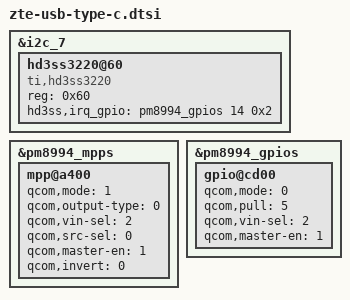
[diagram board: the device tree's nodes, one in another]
/*
 * Copyright (c) 2015 The Linux Foundation. All rights reserved.
 *
 * This program is free software; you can redistribute it and/or modify
 * it under the terms of the GNU General Public License version 2 and
 * only version 2 as published by the Free Software Foundation.
 *
 * This program is distributed in the hope that it will be useful,
 * but WITHOUT ANY WARRANTY; without even the implied warranty of
 * MERCHANTABILITY or FITNESS FOR A PARTICULAR PURPOSE.  See the
 * GNU General Public License for more details.
 */

/* Segment 1: Type-C Chips main DTS config */
&i2c_7 {

	/* TI HD3SS3220 chip */
	hd3ss3220@60 { /* slave id 0x61(ADDR Pin:H) or 0x60(ADDR Pin:L) */
		compatible = "ti,hd3ss3220";
		reg = <0x60>;

		/* Naming PM GPIO ( 14 ) */
		hd3ss,irq_gpio = <&pm8994_gpios 14 0x2>;
	};

};

/* Segment 2: Type-C related PM MPP DTS config */
&pm8994_mpps {

	mpp@a400 { /* MPP 5 */
		/* type-c cc en and 3.0 mux enable */
		qcom,mode = <1>;		/* Digital output */
		qcom,output-type = <0>;		/* CMOS logic */
		qcom,vin-sel = <2>;		/* QPNP_PIN_VIN0 */
		qcom,src-sel = <0>;		/* QPNP_PIN_SEL_FUNC_CONSTANT */
		qcom,master-en = <1>;		/* Enable GPIO */
		qcom,invert = <0>;   /* QPNP_PIN_INVERT_DISABLE */
		status = "okay";
	};

};

/* Segment 3: Type-C related PM GPIO DTS config */
&pm8994_gpios {

	gpio@cd00 {
		/* TYPEC_INT_N CC Interrupt*/
		qcom,mode = <0>;  /* Digital input */
		qcom,pull = <5>;  /* No Pull */
		qcom,vin-sel = <2>;
		qcom,master-en = <1>;		/* Enable GPIO */
		status = "okay";
		};
};
